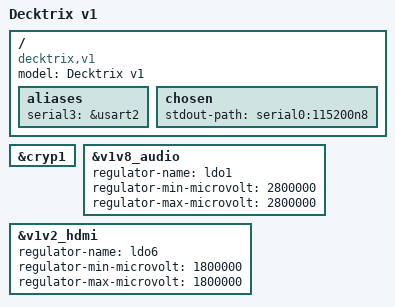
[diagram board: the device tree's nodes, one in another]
// SPDX-License-Identifier: (GPL-2.0+ OR BSD-3-Clause)
/*
 * Copyright (C) Decktrix Lab
 * Author: Kirill Yatsenko <kiriyatsenko@gmail.com>
 *
 * Decktrix v1 custom PCB based on STM32MP157F.
 * Same DDR, clock, and PMIC (STPMIC1) as STM32MP157C-DK2 but
 * LDO1 at 2.8V for display AVDD, LDO6 at 1.8V for display IOVCC.
 */

/dts-v1/;

#include "stm32mp157.dtsi"
#include "stm32mp15xc.dtsi"
#include "stm32mp15-pinctrl.dtsi"
#include "stm32mp15xxac-pinctrl.dtsi"
#include "stm32mp15xx-dkx.dtsi"

/ {
	model = "Decktrix v1";
	compatible = "decktrix,v1", "st,stm32mp157";

	aliases {
		serial3 = &usart2;
	};

	chosen {
		stdout-path = "serial0:115200n8";
	};
};

&cryp1 {
	status = "okay";
};

/* PMIC LDO1: 2.8V for display AVDD (2V8 rail on decktrix PCB) */
&v1v8_audio {
	regulator-name = "ldo1";
	regulator-min-microvolt = <2800000>;
	regulator-max-microvolt = <2800000>;
};

/* PMIC LDO6: 1.8V for display IOVCC (1V8 rail on decktrix PCB) */
&v1v2_hdmi {
	regulator-name = "ldo6";
	regulator-min-microvolt = <1800000>;
	regulator-max-microvolt = <1800000>;
};
